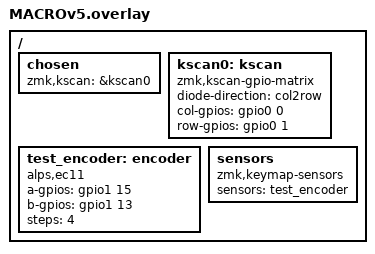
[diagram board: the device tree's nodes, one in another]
#include <dt-bindings/zmk/matrix_transform.h>

/ {
    chosen {
        zmk,kscan = &kscan0;
    };

    /* Minimal kscan to satisfy ZMK requirements */
    kscan0: kscan {
        compatible = "zmk,kscan-gpio-matrix";
        diode-direction = "col2row";
        
        // Single key position (dummy)
        col-gpios = <&gpio0 0 GPIO_ACTIVE_HIGH>;
        row-gpios = <&gpio0 1 (GPIO_ACTIVE_HIGH | GPIO_PULL_DOWN)>;
    };

    /* Encoder Configuration - Focus of this test */
    test_encoder: encoder {
        compatible = "alps,ec11";
        a-gpios = <&gpio1 15 (GPIO_ACTIVE_HIGH | GPIO_PULL_UP)>;
        b-gpios = <&gpio1 13 (GPIO_ACTIVE_HIGH | GPIO_PULL_UP)>;
        steps = <4>; // Highly sensitive for testing
        status = "okay";
    };

    sensors {
        compatible = "zmk,keymap-sensors";
        sensors = <&test_encoder>;
    };
};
